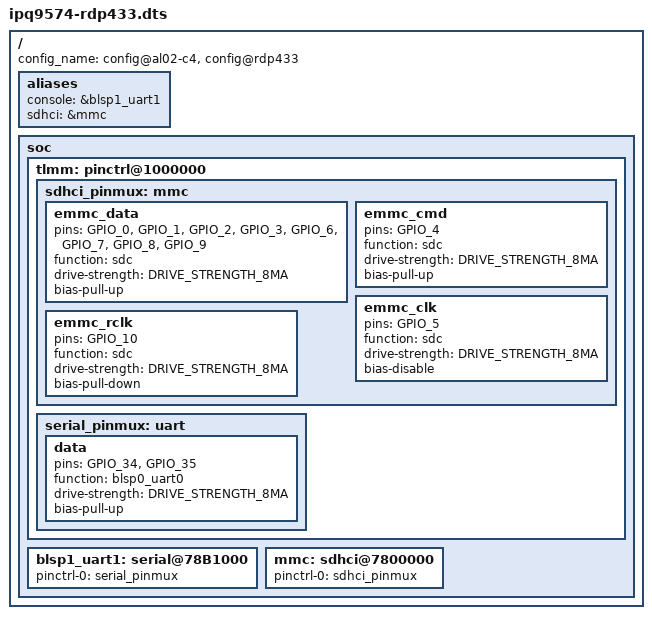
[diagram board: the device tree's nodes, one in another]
// SPDX-License-Identifier: GPL-2.0-only
/*
* Copyright (c) 2023, Qualcomm Innovation Center, Inc. All rights reserved.
*/

/dts-v1/;

#include "ipq9574.dtsi"

/ {
	config_name = "config@al02-c4","config@rdp433";

	aliases {
		console = &blsp1_uart1;
		sdhci = &mmc;
	};

	soc: soc {
		tlmm: pinctrl@1000000 {

			sdhci_pinmux: mmc {
				emmc_data {
					pins = "GPIO_0", "GPIO_1", "GPIO_2",
						"GPIO_3", "GPIO_6", "GPIO_7",
						"GPIO_8", "GPIO_9";
					function = "sdc";
					drive-strength = <DRIVE_STRENGTH_8MA>;
					bias-pull-up;
				};

				emmc_cmd{
					pins = "GPIO_4";
					function = "sdc";
					drive-strength = <DRIVE_STRENGTH_8MA>;
					bias-pull-up;
				};

				emmc_clk{
					pins = "GPIO_5";
					function = "sdc";
					drive-strength = <DRIVE_STRENGTH_8MA>;
					bias-disable;
				};

				emmc_rclk{
					pins = "GPIO_10";
					function = "sdc";
					drive-strength = <DRIVE_STRENGTH_8MA>;
					bias-pull-down;
				};
			};

			serial_pinmux: uart {
				data {
					pins = "GPIO_34", "GPIO_35";
					function = "blsp0_uart0";
					drive-strength = <DRIVE_STRENGTH_8MA>;
					bias-pull-up;
				};
			};
		};


		blsp1_uart1: serial@78B1000 {
			pinctrl-names = "uart";
			pinctrl-0 = <&serial_pinmux>;
			status = "okay";
		};

		mmc: sdhci@7800000 {
			pinctrl-names = "mmc";
			pinctrl-0 = <&sdhci_pinmux>;
			status = "okay";
		};
	};
};
